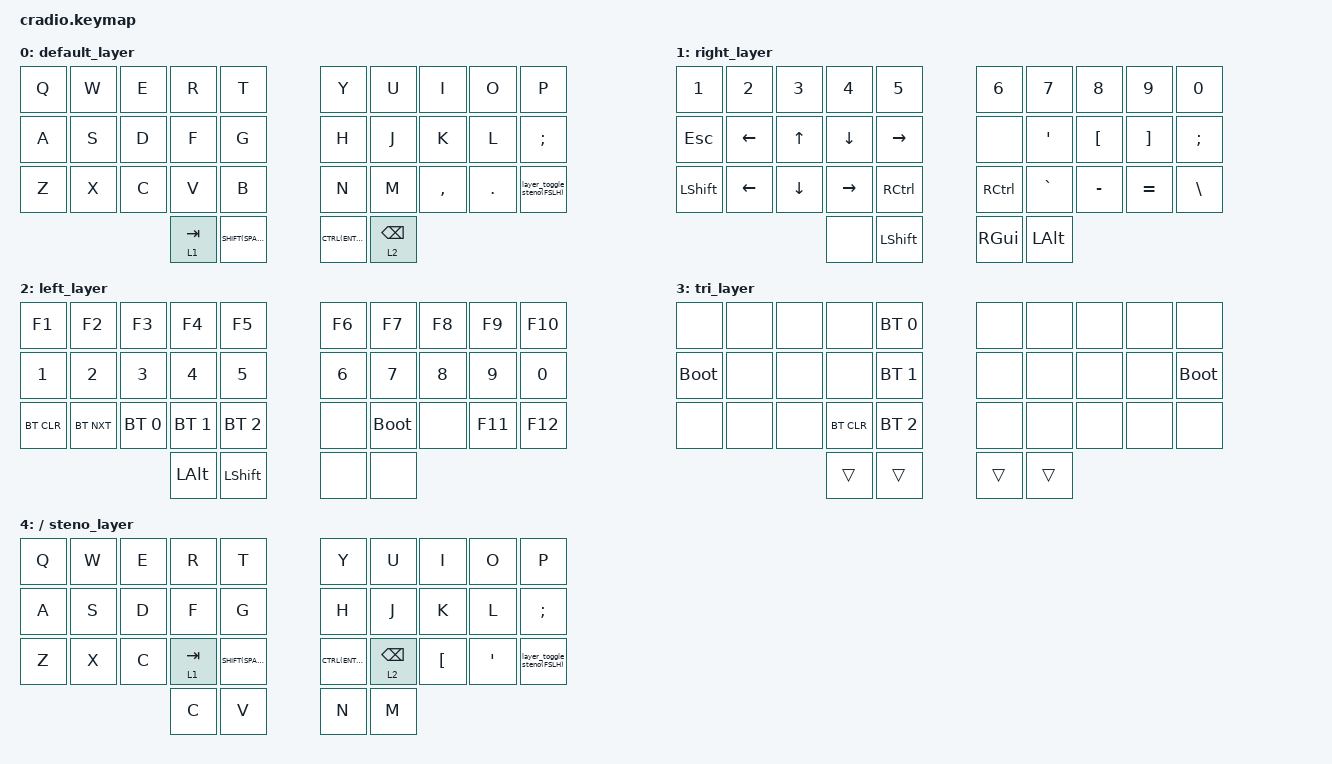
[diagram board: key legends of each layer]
// Copyright (c) 2022 The ZMK Contributors 
// SPDX-License-Identifier: MIT you

#include <behaviors.dtsi>
#include <dt-bindings/zmk/keys.h>
#include <dt-bindings/zmk/bt.h>

// Home row mods macro
#define HRML(k1,k2,k3,k4) &ht LSHFT k1  &ht LCTRL k2  &ht LALT k3  &ht LGUI k4
#define HRMR(k1,k2,k3,k4) &ht RGUI k1  &ht RALT k2  &ht RCTRL k3  &ht RSHFT k4
#define Hyper &ht LC(LA(LS)) k1
#define SHIFT(k1) &ht LSHFT k1
#define CTRL(k1) &ht LCTRL k1

    behaviors {
        ht: hold_tap {
            label = "hold_tap";
            compatible = "zmk,behavior-hold-tap";
            #binding-cells = <2>;
            flavor = "tap-preferred";
            tapping-term-ms = <220>;
            quick-tap-ms = <150>;
            global-quick-tap;
            bindings = <&kp>, <&kp>;
        };
      // Assuming "lt" is a custom or suitably configured behavior
        layer_toggle_steno: lt {
            compatible = "zmk,behavior-layer-toggle";
            label = "Toggle Steno Layer";
            #binding-cells = <1>;
            layer = "steno_layer";
        };
    };

    conditional_layers {
        compatible = "zmk,conditional-layers";
        tri_layer {
            if-layers = <1 2>;
            then-layer = <3>;
        };
    };

    keymap {
        compatible = "zmk,keymap";
        default_layer {
            bindings = <
        //╭──────────┬──────────┬──────────┬──────────┬──────────╮   ╭──────────┬──────────┬──────────┬──────────┬──────────╮
        //│  Q       │  W       │  E       │  R       │  T       │   │  Y       │  U       │  I       │  O       │  P       │
           &kp Q   &kp W      &kp E      &kp R      &kp T          &kp Y      &kp U      &kp I      &kp O      &kp P
        //├──────────┼──────────┼──────────┼──────────┼──────────┤   ├──────────┼──────────┼──────────┼──────────┼──────────┤
        //│  A       │  S       │  D       │  F       │  G       │   │  H       │ J       │  K       │  L       │     ; :  │
           &kp A      &kp S         &kp D         &kp F       &kp G          &kp H      &kp J      &kp K         &kp L       &kp SEMICOLON
        //├──────────┼──────────┼──────────┼──────────┼──────────┤   ├──────────┼──────────┼──────────┼──────────┼──────────┤
        //│  Z       │  X       │  C       │  V       │  B       │   │  N       │  M       │ , <      │ . >      │ / ?      │
           &kp Z      &kp X      &kp C      &kp V      &kp B          &kp N      &kp M      &kp COMMA  &kp DOT    &layer_toggle_steno(FSLH)
        //╰──────────┴──────────┴──────────┼──────────┼──────────┤   ├──────────┼──────────┼──────────┴──────────┴──────────╯
                                            &lt 1 TAB  SHIFT(SPACE)   CTRL(ENTER) &lt 2 BSPC
        //                                 ╰──────────┴──────────╯   ╰──────────┴──────────╯
            >;
        };

        right_layer {
            bindings = <
        //╭──────────┬──────────┬──────────┬──────────┬──────────╮   ╭──────────┬──────────┬──────────┬──────────┬──────────╮
        //│   1 !    │   2 @    │   3 #    │   4 $    │   5 %    │   │   6 ^    │   7 &    │   8 *    │   9 (    │  0 )     │
           &kp N1     &kp N2     &kp N3     &kp N4     &kp N5         &kp N6     &kp N7     &kp N8     &kp N9     &kp N0
        //├──────────┼──────────┼──────────┼──────────┼──────────┤   ├──────────┼──────────┼──────────┼──────────┼──────────┤
        //│ LEFT     │  DOWN    │ UP       │ RIGHT    │   ESC    │   │          │   ' "    │  [ {     │   ] }    │    ; :   │
        
           &kp ESC    &kp LEFT   &kp UP   &kp DOWN    &kp RIGHT       &none   &kp APOS    &kp LBKT       &kp RBKT    &kp SEMICOLON
        //├──────────┼──────────┼──────────┼──────────┼──────────┤   ├──────────┼──────────┼──────────┼──────────┼──────────┤
        //│          │          │          │          │          │   │          │    ` ~   │    - _   │    = +   │   \ |    │
           &kp LSHIFT     &kp LEFT    &kp DOWN &kp RIGHT &kp RCTRL          &kp RCTRL      &kp GRAVE  &kp MINUS  &kp EQUAL  &kp BSLH
        //╰──────────┴──────────┴──────────┼──────────┼──────────┤   ├──────────┼──────────┼──────────┴──────────┴──────────╯
                                           &none         &kp LSHIFT     &kp RGUI      &kp LALT
        //                                 ╰──────────┴──────────╯   ╰──────────┴──────────╯
            >;
        };

        left_layer {
            bindings = <
        //╭──────────┬──────────┬──────────┬──────────┬──────────╮   ╭──────────┬──────────┬──────────┬──────────┬──────────╮
        //│    F1    │    F2    │    F3    │    F4    │    F5    │   │    F6    │    F7    │    F8    │    F9    │    F10   │
           &kp F1     &kp F2     &kp F3     &kp F4     &kp F5         &kp F6     &kp F7     &kp F8     &kp F9     &kp F10
        //├──────────┼──────────┼──────────┼──────────┼──────────┤   ├──────────┼──────────┼──────────┼──────────┼──────────┤
        //│          │          │          │          │          │   │          │          │          │    F11   │    F12   │
           &kp N1     &kp N2     &kp N3     &kp N4     &kp N5         &kp N6     &kp N7     &kp N8     &kp N9     &kp N0
        //├──────────┼──────────┼──────────┼──────────┼──────────┤   ├──────────┼──────────┼──────────┼──────────┼──────────┤
        //│ CLEAR BT │  BT NEXT │          │          │          │   │          │          │          │          │          │
           &bt BT_CLR &bt BT_NXT &bt BT_SEL 0 &bt BT_SEL 1 &bt BT_SEL 2 &none  &bootloader   &none      &kp F11    &kp F12
        //╰──────────┴──────────┴──────────┼──────────┼──────────┤   ├──────────┼──────────┼──────────┴──────────┴──────────╯
                                            &kp LALT     &kp LSHIFT &none    &none 
        //                                 ╰──────────┴──────────╯   ╰──────────┴──────────╯
            >;
        };

        tri_layer {
            bindings = <
        //╭──────────┬──────────┬──────────┬──────────┬──────────╮   ╭──────────┬──────────┬──────────┬──────────┬──────────╮
        //│ RESET    │          │          │          │PROFILE 0 │   │          │          │          │          │  RESET   │
            &none     &none      &none      &none     &bt BT_SEL 0    &none      &none      &none      &none       &none
        //├──────────┼──────────┼──────────┼──────────┼──────────┤   ├──────────┼──────────┼──────────┼──────────┼──────────┤
        //│BOOTLOADER│          │          │          │PROFILE 1 │   │          │          │          │          │BOOTLOADER│
          &bootloader  &none      &none      &none     &bt BT_SEL 1    &none      &none      &none      &none     &bootloader
        //├──────────┼──────────┼──────────┼──────────┼──────────┤   ├──────────┼──────────┼──────────┼──────────┼──────────┤
        //│          │          │          │ CLEAR BT │PROFILE 2 │   │          │          │          │          │          │
            &none      &none      &none     &bt BT_CLR &bt BT_SEL 2    &none      &none      &none      &none      &none
        //╰──────────┴──────────┴──────────┼──────────┼──────────┤   ├──────────┼──────────┼──────────┴──────────┴──────────╯
                                             &trans     &trans         &trans     &trans
        //                                 ╰──────────┴──────────╯   ╰──────────┴──────────╯
            >;
        };
       /

     steno_layer {
            bindings = <
        //╭──────────┬──────────┬──────────┬──────────┬──────────╮   ╭──────────┬──────────┬──────────┬──────────┬──────────╮
        //│  Q       │  W       │  E       │  R       │  T       │   │  Y       │  U       │  I       │  O       │  P       │
           &kp Q   &kp W      &kp E      &kp R      &kp T          &kp Y      &kp U      &kp I      &kp O      &kp P
        //├──────────┼──────────┼──────────┼──────────┼──────────┤   ├──────────┼──────────┼──────────┼──────────┼──────────┤
        //│  A       │  S       │  D       │  F       │  G       │   │  H       │ J       │  K       │  L       │     ; :  │
           &kp A      &kp S         &kp D         &kp F       &kp G          &kp H      &kp J      &kp K         &kp L       &kp SEMICOLON
        //├──────────┼──────────┼──────────┼──────────┼──────────┤   ├──────────┼──────────┼──────────┼──────────┼──────────┤
        //│  Z       │  X       │  C       │  V       │  B       │   │  N       │  M       │ [ <      │   ' >    │ / ?      │
           &kp Z      &kp X      &kp C     &lt 1 TAB  SHIFT(SPACE)      CTRL(ENTER) &lt 2 BSPC     &kp LBKT  &kp APOS    &layer_toggle_steno(FSLH)
        //╰──────────┴──────────┴──────────┼──────────┼──────────┤   ├──────────┼──────────┼──────────┴──────────┴──────────╯
                                              &kp C      &kp V         &kp N      &kp M
        //                                 ╰──────────┴──────────╯   ╰──────────┴──────────╯
            >;
        };

// TODO find package to allow steno natively 
// steno_layer: layer {
            // bindings = <
                // Stenography key layout (Plover/TX Bolt protocol)
                //╭─────────┬─────────┬─────────┬─────────┬─────────╮   ╭─────────┬─────────┬─────────┬─────────┬─────────╮
                //│ STN_NUM │ STN_NUM │ STN_NUM │ STN_NUM │ STN_NUM │   │ STN_NUM │ STN_NUM │ STN_NUM │ STN_NUM │ STN_NUM │
                   &steno STN_NUM  &steno STN_NUM  &steno STN_NUM  &steno STN_NUM  &steno STN_NUM  &steno STN_NUM  &steno STN_NUM  &steno STN_NUM  &steno STN_NUM  &steno STN_NUM
                //├─────────┼─────────┼─────────┼─────────┼─────────┤   ├─────────┼─────────┼─────────┼─────────┼─────────┤
                //│ STN_S1  │ STN_TL  │ STN_PL  │ STN_HL  │ STN_ST1 │   │ STN_ST3 │ STN_FR  │ STN_PR  │ STN_LR  │ STN_TR  │
                   &steno STN_S1   &steno STN_TL   &steno STN_PL   &steno STN_HL   &steno STN_ST1  &steno STN_ST3  &steno STN_FR   &steno STN_PR   &steno STN_LR   &steno STN_TR
                //├─────────┼─────────┼─────────┼─────────┼─────────┤   ├─────────┼─────────┼─────────┼─────────┼─────────┤
                //│ STN_A   │ STN_O   │         │         │ STN_E   │   │ STN_U   │         │         │ STN_EU  │ STN_NUM │
                     &none       &none    &none       &none           &none    &none    &none           &none           &steno STN_EU   &layer_toggle_steno
                //╰─────────┴─────────┴─────────┼─────────┼─────────┤   ├─────────┼─────────┼─────────┴─────────┴─────────╯
                                                &steno STN_A     &steno STN_O     &steno STN_E &steno STN_U
                //                              ╰─────────┴─────────╯   ╰─────────┴─────────╯
           // >; 
 // };


    };
};
